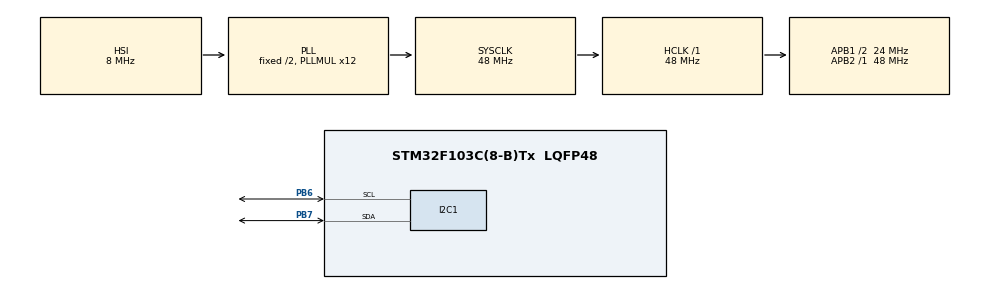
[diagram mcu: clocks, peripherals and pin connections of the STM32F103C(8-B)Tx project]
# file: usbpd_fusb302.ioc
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Dma.I2C1_RX.0.Direction=DMA_PERIPH_TO_MEMORY
Dma.I2C1_RX.0.Instance=DMA1_Channel7
Dma.I2C1_RX.0.MemDataAlignment=DMA_MDATAALIGN_BYTE
Dma.I2C1_RX.0.MemInc=DMA_MINC_ENABLE
Dma.I2C1_RX.0.Mode=DMA_NORMAL
Dma.I2C1_RX.0.PeriphDataAlignment=DMA_PDATAALIGN_BYTE
Dma.I2C1_RX.0.PeriphInc=DMA_PINC_DISABLE
Dma.I2C1_RX.0.Priority=DMA_PRIORITY_LOW
Dma.I2C1_TX.1.Direction=DMA_MEMORY_TO_PERIPH
Dma.I2C1_TX.1.Instance=DMA1_Channel6
Dma.I2C1_TX.1.MemDataAlignment=DMA_MDATAALIGN_BYTE
Dma.I2C1_TX.1.MemInc=DMA_MINC_ENABLE
Dma.I2C1_TX.1.Mode=DMA_NORMAL
Dma.I2C1_TX.1.PeriphDataAlignment=DMA_PDATAALIGN_BYTE
Dma.I2C1_TX.1.PeriphInc=DMA_PINC_DISABLE
Dma.I2C1_TX.1.Priority=DMA_PRIORITY_LOW
Dma.Request0=I2C1_RX
Dma.Request1=I2C1_TX
I2C1.I2C_Mode=I2C_Fast
Mcu.Family=STM32F1
Mcu.Name=STM32F103C(8-B)Tx
Mcu.Package=LQFP48
NVIC.DMA1_Channel6_IRQn=true\:0\:0\:false\:false\:true\:false\:true
NVIC.DMA1_Channel7_IRQn=true\:0\:0\:false\:false\:true\:false\:true
NVIC.PriorityGroup=NVIC_PRIORITYGROUP_4
PA13.Mode=Serial_Wire
PA13.Signal=SYS_JTMS-SWDIO
PA14.Mode=Serial_Wire
PA14.Signal=SYS_JTCK-SWCLK
PB6.GPIO_Mode=GPIO_MODE_AF_OD
PB6.Mode=I2C
PB6.Signal=I2C1_SCL
PB7.Mode=I2C
PB7.Signal=I2C1_SDA
PD0-OSC_IN.Mode=HSE-External-Oscillator
PD0-OSC_IN.Signal=RCC_OSC_IN
PD1-OSC_OUT.Mode=HSE-External-Oscillator
PD1-OSC_OUT.Signal=RCC_OSC_OUT
ProjectManager.HeapSize=0x200
ProjectManager.StackSize=0x400
ProjectManager.TargetToolchain=STM32CubeIDE
RCC.AHBFreq_Value=48000000
RCC.APB1CLKDivider=RCC_HCLK_DIV2
RCC.APB1Freq_Value=24000000
RCC.APB1TimFreq_Value=48000000
RCC.APB2Freq_Value=48000000
RCC.APB2TimFreq_Value=48000000
RCC.HCLKFreq_Value=48000000
RCC.PLLMUL=RCC_PLL_MUL12
RCC.SYSCLKFreq_VALUE=48000000
RCC.SYSCLKSource=RCC_SYSCLKSOURCE_PLLCLK
RCC.USBFreq_Value=48000000
TIM2.Prescaler=48-1
VP_TIM1_VS_ClockSourceINT.Mode=Internal
VP_TIM2_VS_ClockSourceINT.Mode=Internal
VP_TIM3_VS_ClockSourceINT.Mode=Internal
board=custom

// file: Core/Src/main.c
/* USER CODE BEGIN Header */
/**
 ******************************************************************************
 * @file           : main.c
 * @brief          : Main program body
 ******************************************************************************
 * @attention
 *
 * Copyright (c) 2022 STMicroelectronics.
 * All rights reserved.
 *
 * This software is licensed under terms that can be found in the LICENSE file
 * in the root directory of this software component.
 * If no LICENSE file comes with this software, it is provided AS-IS.
 *
 ******************************************************************************
 */
/* USER CODE END Header */
#include "main.h"

/* USER CODE BEGIN Includes */
#include "core.h"
#include "dpm.h"
#include "HWIO.h"
#include "Timing.h"
#include "PlatformI2C.h"
#include "HostComm.h"
#include "PD_Types.h"
#include "PDPolicy.h"

#ifdef FSC_DEBUG
#include "usbd_main.h"
#include "usbd_desc.h"
#include "usbd_hid.h"
#endif /* FSC_DEBUG */

#include "stm32f1xx.h"

#include "FSCTypes.h"

#include "fan6295.h"
#include "PDProtocol.h"

/* USER CODE END Includes */

I2C_HandleTypeDef hi2c1;
DMA_HandleTypeDef hdma_i2c1_rx;
DMA_HandleTypeDef hdma_i2c1_tx;

TIM_HandleTypeDef htim1;
TIM_HandleTypeDef htim2;
TIM_HandleTypeDef htim3;

void SystemClock_Config(void);
static void MX_GPIO_Init(void);
static void MX_DMA_Init(void);
static void MX_I2C1_Init(void);
static void MX_TIM1_Init(void);
static void MX_TIM3_Init(void);
static void MX_TIM2_Init(void);
/* USER CODE BEGIN PFP */

static const uint8_t FUSB102_ADDR = 0x22 << 1; // Use 8-bit address
static const uint8_t REG_DEVICE_ID = 0x01;

volatile FSC_BOOL haveINTReady = FALSE;

#ifdef FSC_DEBUG
volatile FSC_BOOL haveUSBInMsg = FALSE;

void platform_set_debug(FSC_U8 port, FSC_BOOL enable);
#endif /* FSC_DEBUG */

/*******************************************************************************
 * Static variables
 ******************************************************************************/
static DevicePolicyPtr_t dpm;
static Port_t ports[NUM_PORTS]; /* Array of ports */
/* USER CODE END PFP */

/* USER CODE BEGIN 0 */
static void InitializeBoard(void) {
#ifdef FSC_DEBUG
    /* Initialize Host com */
    HCom_Init(ports, 1);
    /* Initialize the USB interface */
    InitializeUSB();
#endif /* FSC_DEBUG */
}

static void InitializeSystem(void) {
	InitializeBoard();
	InitializeTickTimer();
	InitializeTSTimer();
}

void platform_set_debug(FSC_U8 port, FSC_BOOL enable) {

}

void handle_core_event(int event, int portid, void *usr_ctx, void *app_ctx) {
       doDataObject_t pdo;
       if (event & PD_NEW_CONTRACT)
       {
//          pdo = (doDataObject_t*)app_ctx;
          /* handle event */
} }

/* USER CODE END 0 */

int main(void)
{
  /* USER CODE BEGIN 1 */
	HAL_StatusTypeDef ret;
	uint8_t bufin[1];
	uint8_t bufout[1];
	uint8_t bufout2[1];

  /* USER CODE END 1 */

  /* MCU Configuration--------------------------------------------------------*/

  /* Reset of all peripherals, Initializes the Flash interface and the Systick. */
  HAL_Init();

  /* USER CODE BEGIN Init */
	HAL_InitTick(1);
  /* USER CODE END Init */

  /* Configure the system clock */
  SystemClock_Config();

  /* Initialize all configured peripherals */
  MX_GPIO_Init();
  MX_DMA_Init();
  MX_I2C1_Init();
  MX_TIM1_Init();
  MX_TIM3_Init();
  MX_TIM2_Init();
  /* USER CODE BEGIN 2 */
	while (1) {
		bufin[0] = REG_DEVICE_ID;
		ret = HAL_I2C_Master_Transmit(&hi2c1, FUSB300SlaveAddr, bufin, 1,
				3000);
		if (ret != HAL_OK) {
		} else {
			// Read 2 bytes from the temperature register
			ret = HAL_I2C_Master_Receive(&hi2c1, FUSB102_ADDR, bufout, 1,
					3000);
			if (ret == HAL_OK) {
			}
		}

		FSC_BOOL status = DeviceRead(FUSB300SlaveAddr, regDeviceID, 1, bufout2);
		if (status == TRUE) {
			break;
		}
	}
  /* USER CODE END 2 */

  /* Infinite loop */
  /* USER CODE BEGIN WHILE */
	FSC_U32 timer_value;

	InitializeSystem();

	DPM_Init(&dpm);

	ports[0].dpm = dpm;
	ports[0].PortID = 0;
//	&ports[0]->PortConfig.SinkUSBSuspendOperation = TRUE;
//	&ports[0]->PortConfig.SinkUSBCommCapable = TRUE;
	core_initialize(&ports[0], FUSB300SlaveAddr);

	DPM_AddPort(dpm, &ports[0]);
	register_observer(EVENT_ALL, handle_core_event, 0);

#ifdef FSC_HAVE_PPS_SOURCE
      FAN6295_Initialize();
  #endif /* FSC_HAVE_PPS_SOURCE */

#ifdef FSC_DEBUG
      platform_set_debug(ports[0].PortID,FALSE);
  #endif /* FSC_DEBUG */

	while (1) {
//  #ifdef this
		haveINTReady = TRUE;
//  #endif /* FSC_POLLING_MODE */

		/* Run the Type-C state machine */
		if (haveINTReady
#ifdef FSC_DEBUG
                  || haveUSBInMsg
  #endif /* FSC_DEBUG */
		) {
			/* Disable the timer interrupt */
			ClearTimeInterrupt();

			/* Optional: Enable system timer(s) here if they were previously
			 * disabled while in Idle mode.
			 */

#ifdef FSC_DEBUG
              platform_set_debug(ports[0].PortID,TRUE);
  #endif /* FSC_DEBUG */

			core_state_machine(&ports[0]);
			if(ports[0].ConnState == AttachedSink && &ports[0].PolicyState == peSinkTransitionDefault) {
//				UpdateCapabilitiesRx(&ports[0], TRUE);
//				PolicySinkEvaluateCaps(&ports[0]);
			} else
			if(ports[0].ConnState == AttachedSink ) {
//				SetPEState(&ports[0], peSinkGetSourceCap);
//				ProtocolGetRxPacket(&ports[0], FALSE);
//				UpdateCapabilitiesRx(&ports[0], TRUE);
//				ProtocolFlushRxFIFO(&ports[0]);
//				  ports[0].SinkRequest.BRDO = ports[0].SrcCapsReceived[2].BRDO;
//				SetPEState(&ports[0], peSinkSelectCapability);
//				ProtocolTransmitMessage(&ports[0]);
//				ProtocolFlushTxFIFO(&ports[0]);
//				ProtocolSendingMessage(&ports[0]);
//				SetStateAttachedSink(&ports[0]);
//				UpdateCapabilitiesRx(&ports[0], TRUE);
//				PolicySinkEvaluateCaps(&ports[0]);
//				PolicySinkSelectCapability(&ports[0]);
			}
			if(ports[0].ConnState == Unattached) {
//				ProtocolFlushRxFIFO(&ports[0]);
			}

#ifdef FSC_DEBUG
              platform_set_debug(ports[0].PortID,FALSE);
  #endif /* FSC_DEBUG */

			haveINTReady = FALSE;

			/*
			 * It is possible for the state machine to go into idle mode with
			 * the interrupt pin still low and as a result the edge-sensitive
			 * IRQ won't get triggered.  Check here before returning to wait
			 * on the IRQ.
			 */
			if (platform_get_device_irq_state(ports[0].PortID)) {
				haveINTReady = TRUE;
			} else {
				/* If needed, enable timer interrupt before idling */
				timer_value = core_get_next_timeout(&ports[0]);

				if (timer_value > 0) {
					if (timer_value == 1) {
						/* A value of 1 indicates that a timer has expired
						 * or is about to expire and needs further processing.
						 */
						haveINTReady = TRUE;
					} else {
						/* A non-zero time requires a future timer interrupt */
						SetTimeInterrupt(timer_value);
					}
				} else {
					/* Optional: Disable system timer(s) here to save power
					 * if needed while in Idle mode.
					 */
				}
			}
		}

#ifdef FSC_DEBUG
		HCom_Process();
          if (haveUSBInMsg)
          {
            /* Process the message */

            /* Send response */
            USBD_HID_SendReport(&USBD_Device, HCom_OutBuf(),
                USBD_HID_OUTREPORT_BUF_SIZE);

            haveUSBInMsg = FALSE;
          }
  #endif /* FSC_DEBUG */
	}
    /* USER CODE END WHILE */

}

void SystemClock_Config(void)
{
  RCC_OscInitTypeDef RCC_OscInitStruct = {0};
  RCC_ClkInitTypeDef RCC_ClkInitStruct = {0};

  /** Initializes the RCC Oscillators according to the specified parameters
  * in the RCC_OscInitTypeDef structure.
  */
  RCC_OscInitStruct.OscillatorType = RCC_OSCILLATORTYPE_HSI;
  RCC_OscInitStruct.HSIState = RCC_HSI_ON;
  RCC_OscInitStruct.HSICalibrationValue = RCC_HSICALIBRATION_DEFAULT;
  RCC_OscInitStruct.PLL.PLLState = RCC_PLL_ON;
  RCC_OscInitStruct.PLL.PLLSource = RCC_PLLSOURCE_HSI_DIV2;
  RCC_OscInitStruct.PLL.PLLMUL = RCC_PLL_MUL12;
  if (HAL_RCC_OscConfig(&RCC_OscInitStruct) != HAL_OK)
  {
    Error_Handler();
  }
  /** Initializes the CPU, AHB and APB buses clocks
  */
  RCC_ClkInitStruct.ClockType = RCC_CLOCKTYPE_HCLK|RCC_CLOCKTYPE_SYSCLK
                              |RCC_CLOCKTYPE_PCLK1|RCC_CLOCKTYPE_PCLK2;
  RCC_ClkInitStruct.SYSCLKSource = RCC_SYSCLKSOURCE_PLLCLK;
  RCC_ClkInitStruct.AHBCLKDivider = RCC_SYSCLK_DIV1;
  RCC_ClkInitStruct.APB1CLKDivider = RCC_HCLK_DIV2;
  RCC_ClkInitStruct.APB2CLKDivider = RCC_HCLK_DIV1;

  if (HAL_RCC_ClockConfig(&RCC_ClkInitStruct, FLASH_LATENCY_1) != HAL_OK)
  {
    Error_Handler();
  }
}

static void MX_I2C1_Init(void)
{

  hi2c1.Instance = I2C1;
  hi2c1.Init.ClockSpeed = 400000;
  hi2c1.Init.DutyCycle = I2C_DUTYCYCLE_2;
  hi2c1.Init.OwnAddress1 = 0;
  hi2c1.Init.AddressingMode = I2C_ADDRESSINGMODE_7BIT;
  hi2c1.Init.DualAddressMode = I2C_DUALADDRESS_DISABLE;
  hi2c1.Init.OwnAddress2 = 0;
  hi2c1.Init.GeneralCallMode = I2C_GENERALCALL_DISABLE;
  hi2c1.Init.NoStretchMode = I2C_NOSTRETCH_DISABLE;
  if (HAL_I2C_Init(&hi2c1) != HAL_OK)
  {
    Error_Handler();
  }

}

static void MX_TIM1_Init(void)
{

  TIM_ClockConfigTypeDef sClockSourceConfig = {0};
  TIM_MasterConfigTypeDef sMasterConfig = {0};

  htim1.Instance = TIM1;
  htim1.Init.Prescaler = 0;
  htim1.Init.CounterMode = TIM_COUNTERMODE_UP;
  htim1.Init.Period = 65535;
  htim1.Init.ClockDivision = TIM_CLOCKDIVISION_DIV1;
  htim1.Init.RepetitionCounter = 0;
  htim1.Init.AutoReloadPreload = TIM_AUTORELOAD_PRELOAD_DISABLE;
  if (HAL_TIM_Base_Init(&htim1) != HAL_OK)
  {
    Error_Handler();
  }
  sClockSourceConfig.ClockSource = TIM_CLOCKSOURCE_INTERNAL;
  if (HAL_TIM_ConfigClockSource(&htim1, &sClockSourceConfig) != HAL_OK)
  {
    Error_Handler();
  }
  sMasterConfig.MasterOutputTrigger = TIM_TRGO_RESET;
  sMasterConfig.MasterSlaveMode = TIM_MASTERSLAVEMODE_DISABLE;
  if (HAL_TIMEx_MasterConfigSynchronization(&htim1, &sMasterConfig) != HAL_OK)
  {
    Error_Handler();
  }

}

static void MX_TIM2_Init(void)
{

  TIM_ClockConfigTypeDef sClockSourceConfig = {0};
  TIM_MasterConfigTypeDef sMasterConfig = {0};

  htim2.Instance = TIM2;
  htim2.Init.Prescaler = 48-1;
  htim2.Init.CounterMode = TIM_COUNTERMODE_UP;
  htim2.Init.Period = 65535;
  htim2.Init.ClockDivision = TIM_CLOCKDIVISION_DIV1;
  htim2.Init.AutoReloadPreload = TIM_AUTORELOAD_PRELOAD_DISABLE;
  if (HAL_TIM_Base_Init(&htim2) != HAL_OK)
  {
    Error_Handler();
  }
  sClockSourceConfig.ClockSource = TIM_CLOCKSOURCE_INTERNAL;
  if (HAL_TIM_ConfigClockSource(&htim2, &sClockSourceConfig) != HAL_OK)
  {
    Error_Handler();
  }
  sMasterConfig.MasterOutputTrigger = TIM_TRGO_RESET;
  sMasterConfig.MasterSlaveMode = TIM_MASTERSLAVEMODE_DISABLE;
  if (HAL_TIMEx_MasterConfigSynchronization(&htim2, &sMasterConfig) != HAL_OK)
  {
    Error_Handler();
  }

}

static void MX_TIM3_Init(void)
{

  TIM_ClockConfigTypeDef sClockSourceConfig = {0};
  TIM_MasterConfigTypeDef sMasterConfig = {0};

  htim3.Instance = TIM3;
  htim3.Init.Prescaler = 0;
  htim3.Init.CounterMode = TIM_COUNTERMODE_UP;
  htim3.Init.Period = 65535;
  htim3.Init.ClockDivision = TIM_CLOCKDIVISION_DIV1;
  htim3.Init.AutoReloadPreload = TIM_AUTORELOAD_PRELOAD_DISABLE;
  if (HAL_TIM_Base_Init(&htim3) != HAL_OK)
  {
    Error_Handler();
  }
  sClockSourceConfig.ClockSource = TIM_CLOCKSOURCE_INTERNAL;
  if (HAL_TIM_ConfigClockSource(&htim3, &sClockSourceConfig) != HAL_OK)
  {
    Error_Handler();
  }
  sMasterConfig.MasterOutputTrigger = TIM_TRGO_RESET;
  sMasterConfig.MasterSlaveMode = TIM_MASTERSLAVEMODE_DISABLE;
  if (HAL_TIMEx_MasterConfigSynchronization(&htim3, &sMasterConfig) != HAL_OK)
  {
    Error_Handler();
  }

}

static void MX_DMA_Init(void)
{

  /* DMA controller clock enable */
  __HAL_RCC_DMA1_CLK_ENABLE();

  /* DMA interrupt init */
  /* DMA1_Channel6_IRQn interrupt configuration */
  HAL_NVIC_SetPriority(DMA1_Channel6_IRQn, 0, 0);
  HAL_NVIC_EnableIRQ(DMA1_Channel6_IRQn);
  /* DMA1_Channel7_IRQn interrupt configuration */
  HAL_NVIC_SetPriority(DMA1_Channel7_IRQn, 0, 0);
  HAL_NVIC_EnableIRQ(DMA1_Channel7_IRQn);

}

static void MX_GPIO_Init(void)
{

  /* GPIO Ports Clock Enable */
  __HAL_RCC_GPIOD_CLK_ENABLE();
  __HAL_RCC_GPIOA_CLK_ENABLE();
  __HAL_RCC_GPIOB_CLK_ENABLE();

}

void Error_Handler(void)
{
	__disable_irq();
	while (1) {
	}
}
